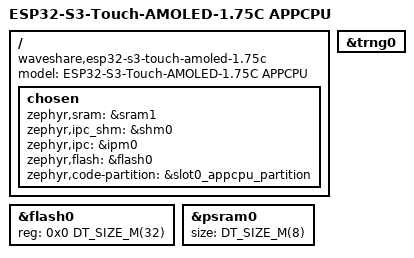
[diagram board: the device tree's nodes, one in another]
/*
 * Copyright (c) 2026 Hassan Naeem
 * SPDX-License-Identifier: Apache-2.0
 */

/dts-v1/;
#include <espressif/esp32s3/esp32s3.dtsi>
#include <espressif/partitions_0x0_amp_32M.dtsi>

/ {
	compatible = "waveshare,esp32-s3-touch-amoled-1.75c";
	model = "ESP32-S3-Touch-AMOLED-1.75C APPCPU";

	chosen {
		zephyr,sram = &sram1;
		zephyr,ipc_shm = &shm0;
		zephyr,ipc = &ipm0;
		zephyr,flash = &flash0;
		zephyr,code-partition = &slot0_appcpu_partition;
	};
};

&flash0 {
	reg = <0x0 DT_SIZE_M(32)>;
	ranges = <0x0 0x0 DT_SIZE_M(32)>;
};

&psram0 {
	size = <DT_SIZE_M(8)>;
};

&trng0 {
	status = "okay";
};
